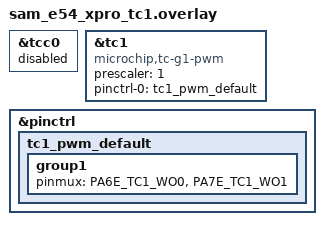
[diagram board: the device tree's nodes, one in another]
/*
 * Copyright (c) 2025 Microchip Technology Inc.
 *
 * SPDX-License-Identifier: Apache-2.0
 */

&tcc0 {
	status = "disabled";
};

&tc1 {
	status = "okay";
	compatible = "microchip,tc-g1-pwm";
	prescaler = <1>;
	#pwm-cells = <3>;
	pinctrl-0 = <&tc1_pwm_default>;
	pinctrl-names = "default";
};

&pinctrl {
	tc1_pwm_default: tc1_pwm_default {
		group1 {
			pinmux = <PA6E_TC1_WO0>,
				 <PA7E_TC1_WO1>;
		};
	};
};
